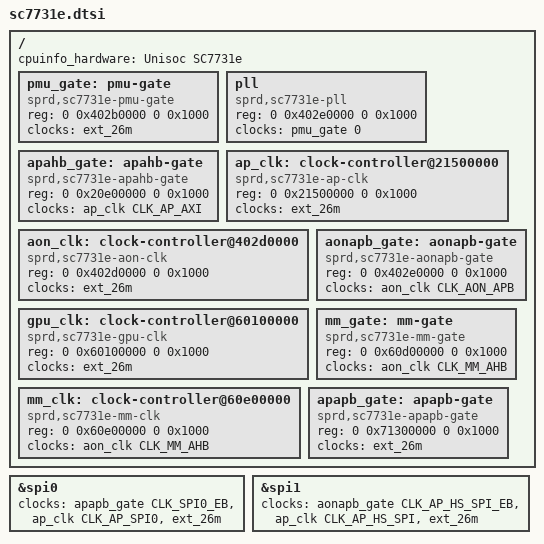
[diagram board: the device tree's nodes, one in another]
/*
 * Spreadtrum SC7731e SoC DTS file
 *
 * Copyright (C) 2019, Spreadtrum Communications Inc.
 *
 * This file is licensed under a dual GPLv2 or X11 license.
 */

#include "pike2.dtsi"

/ {
	cpuinfo_hardware = "Unisoc SC7731e";

	pmu_gate: pmu-gate {
		compatible = "sprd,sc7731e-pmu-gate";
		/*sprd,syscon = <&pmu_apb_regs>;*/ /* 0x402b0000 */
		reg = <0 0x402b0000 0 0x1000>;
		clocks = <&ext_26m>;
		#clock-cells = <1>;
	};

	pll: pll {
		compatible = "sprd,sc7731e-pll";
		/*sprd,syscon = <&aon_apb_regs>;*/ /* 0x402e0000 */
		reg = <0 0x402e0000 0 0x1000>;
		clocks = <&pmu_gate 0>;
		#clock-cells = <1>;
	};

	apahb_gate: apahb-gate {
		compatible = "sprd,sc7731e-apahb-gate";
		/*sprd,syscon = <&ap_ahb_regs>;*/ /* 0x20e00000 */
		reg = <0 0x20e00000 0 0x1000>;
		clocks = <&ap_clk CLK_AP_AXI>;
		#clock-cells = <1>;
	};

	ap_clk: clock-controller@21500000 {
		compatible = "sprd,sc7731e-ap-clk"; /* 0x21500000 */
		reg = <0 0x21500000 0 0x1000>;
		clocks = <&ext_26m>;
		#clock-cells = <1>;
	};

	aon_clk: clock-controller@402d0000 {
		compatible = "sprd,sc7731e-aon-clk"; /* 0x402d0000 */
		reg = <0 0x402d0000 0 0x1000>;
		clocks = <&ext_26m>;
		#clock-cells = <1>;
	};

	aonapb_gate: aonapb-gate {
		compatible = "sprd,sc7731e-aonapb-gate";
		/*sprd,syscon = <&aon_apb_regs>;*/ /* 0x402e0000 */
		reg = <0 0x402e0000 0 0x1000>;
		clocks = <&aon_clk CLK_AON_APB>;
		#clock-cells = <1>;
	};

	gpu_clk: clock-controller@60100000 {
		compatible = "sprd,sc7731e-gpu-clk";
		/*sprd,syscon = <&gpu_ahb_regs>;*/ /* 0x60100000 */
		reg = <0 0x60100000 0 0x1000>;
		clocks = <&ext_26m>;
		#clock-cells = <1>;
	};

	mm_gate: mm-gate {
		compatible = "sprd,sc7731e-mm-gate";
		/*sprd,syscon = <&mm_ahb_regs>;*/ /* 0x60d00000 */
		reg = <0 0x60d00000 0 0x1000>;
		clocks = <&aon_clk CLK_MM_AHB>;
		#clock-cells = <1>;
	};

	mm_clk: clock-controller@60e00000 {
		compatible = "sprd,sc7731e-mm-clk";
		reg = <0 0x60e00000 0 0x1000>; /* 0x60e00000 */
		clocks = <&aon_clk CLK_MM_AHB>;
		#clock-cells = <1>;
	};

	apapb_gate: apapb-gate {
		compatible = "sprd,sc7731e-apapb-gate";
		/*sprd,syscon = <&ap_apb_regs>;*/ /* 0x71300000 */
		reg = <0 0x71300000 0 0x1000>;
		clocks = <&ext_26m>;
		#clock-cells = <1>;
	};
};

&spi0 {
	clock-names = "enable", "spi", "source";
	clocks = <&apapb_gate CLK_SPI0_EB>,
	<&ap_clk CLK_AP_SPI0>, <&ext_26m>;
};

&spi1 {
	clock-names = "enable", "spi", "source";
	clocks = <&aonapb_gate CLK_AP_HS_SPI_EB>,
	<&ap_clk CLK_AP_HS_SPI>, <&ext_26m>;
};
